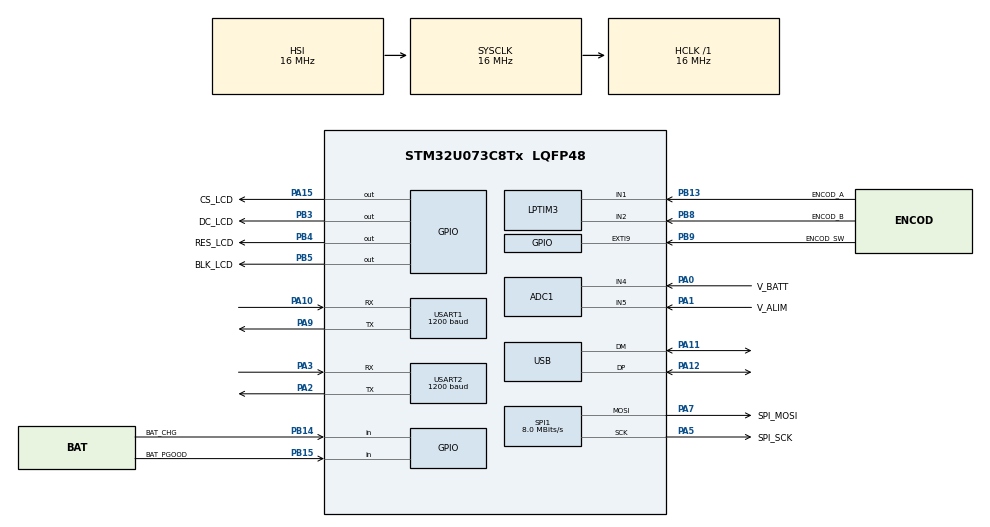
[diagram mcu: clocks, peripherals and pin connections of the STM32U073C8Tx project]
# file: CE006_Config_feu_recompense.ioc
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ADC1.Channel-0\#ChannelRegularConversion=ADC_CHANNEL_4
ADC1.NbrOfConversionFlag=1
ADC1.Rank-0\#ChannelRegularConversion=1
ADC1.RankArg-0\#ChannelRegularConversion=ADC_REGULAR_RANK_1
ADC1.SamplingTime-0\#ChannelRegularConversion=ADC_SAMPLINGTIME_COMMON_1
ADC1.SelectedChannel=ADC_CHANNEL_4|ADC_CHANNEL_5
ADC1.master=1
Mcu.Family=STM32U0
Mcu.Name=STM32U073C8Tx
Mcu.Package=LQFP48
NVIC.EXTI4_15_IRQn=true\:0\:0\:false\:false\:true\:false\:true\:true\:true
NVIC.PriorityGroup=NVIC_PRIORITYGROUP_2
NVIC.TIM1_BRK_UP_TRG_COM_IRQn=true\:3\:0\:false\:false\:true\:false\:false\:true\:true
NVIC.TimeBase=TIM1_BRK_UP_TRG_COM_IRQn
NVIC.TimeBaseIP=TIM1
PA0.GPIO_Label=V_BATT
PA0.Mode=IN4
PA0.Signal=ADC1_IN4
PA1.GPIO_Label=V_ALIM
PA1.Mode=IN5
PA1.Signal=ADC1_IN5
PA10.Mode=Asynchronous
PA10.Signal=USART1_RX
PA11\ [PA9].Mode=Device
PA11\ [PA9].Signal=USB_DM
PA12\ [PA10].Mode=Device
PA12\ [PA10].Signal=USB_DP
PA13\ (SWDIO).GPIO_Label=SWDIO
PA13\ (SWDIO).Signal=DEBUG_JTMS-SWDIO
PA14\ (SWCLK).GPIO_Label=SWCLK
PA14\ (SWCLK).Signal=DEBUG_JTCK-SWCLK
PA15.GPIO_Label=CS_LCD
PA15.Signal=GPIO_Output
PA2.Mode=Asynchronous
PA2.Signal=USART2_TX
PA3.Mode=Asynchronous
PA3.Signal=USART2_RX
PA5.GPIO_Label=SPI_SCK
PA5.Mode=TX_Only_Simplex_Unidirect_Master
PA5.Signal=SPI1_SCK
PA7.GPIO_Label=SPI_MOSI
PA7.Mode=TX_Only_Simplex_Unidirect_Master
PA7.Signal=SPI1_MOSI
PA9.Mode=Asynchronous
PA9.Signal=USART1_TX
PB13.GPIO_Label=ENCOD_A
PB13.Mode=Encoder_mode_occur1
PB13.Signal=LPTIM3_IN1
PB14.GPIO_Label=BAT_CHG
PB14.Signal=GPIO_Input
PB15.GPIO_Label=BAT_PGOOD
PB15.Signal=GPIO_Input
PB3.GPIO_Label=DC_LCD
PB3.Signal=GPIO_Output
PB4.GPIO_Label=RES_LCD
PB4.Signal=GPIO_Output
PB5.GPIO_Label=BLK_LCD
PB5.Signal=GPIO_Output
PB8.GPIO_Label=ENCOD_B
PB8.Mode=Encoder_mode_occur1
PB8.Signal=LPTIM3_IN2
PB9.GPIO_Label=ENCOD_SW
PB9.Signal=GPXTI9
PF0-OSC_IN.Mode=HSE-External-Oscillator
PF0-OSC_IN.Signal=RCC_OSC_IN
PF1-OSC_OUT.Mode=HSE-External-Oscillator
PF1-OSC_OUT.Signal=RCC_OSC_OUT
ProjectManager.HeapSize=0x200
ProjectManager.StackSize=0x400
ProjectManager.TargetToolchain=STM32CubeIDE
RCC.AHBFreq_Value=16000000
RCC.CortexFreq_Value=16000000
RCC.HCLKFreq_Value=16000000
RCC.HSE_VALUE=4000000
RCC.HSI48_VALUE=48000000
RCC.HSI_VALUE=16000000
RCC.LSE_VALUE=32768
RCC.MSI_VALUE=4000000
RCC.SYSCLKFreq_VALUE=16000000
RCC.USBCLockSelection=RCC_USBCLKSOURCE_HSI48
RCC.USBFreq_Value=48000000
RCC.VCOOutputFreq_Value=64000000
SPI1.CalculateBaudRate=8.0 MBits/s
SPI1.Direction=SPI_DIRECTION_2LINES
SPI1.Mode=SPI_MODE_MASTER
SPI1.VirtualType=VM_MASTER
USART1.BaudRate=1200
USART1.Parity=PARITY_ODD
USART1.VirtualMode-Asynchronous=VM_ASYNC
USART1.WordLength=WORDLENGTH_7B
USART2.BaudRate=1200
USART2.Parity=PARITY_ODD
USART2.VirtualMode-Asynchronous=VM_ASYNC
USART2.WordLength=WORDLENGTH_7B
USB.VirtualMode=Device_Only
USBX.BSP.number=1
USBX.Core_System=1
USBX.USBD_CDCACM_EPIN_ADDR=2
USBX.USBD_CDCACM_EPOUT_ADDR=3
USBX.UX_DEVICE_CDC_ACM=1
USBX.UX_Device_Controller=1
USBX.UX_Device_CoreStack=1
USBX0.BSP.STBoard=false
USBX0.BSP.api=Unknown
USBX0.BSP.instance=USB
USBX0.BSP.ip=USB
USBX0.BSP.mode=Device_Only
USBX0.BSP.name=USB_Device
USBX0.BSP.solution=USB
VP_PWR_VS_SECSignals.Mode=Security/Privilege
VP_SYS_VS_tim1.Mode=TIM1
VP_THREADX_VS_RTOSJjThreadXJjCoreJjDefault.Mode=Core_Default
VP_USBX_Core_System.Mode=Core_System
VP_USBX_UX\ Device\ CDC\ ACM\ Class_FS.Mode=UX_Device_class_CDC_ACM_FS
VP_USBX_UX\ Device\ Controller_FS.Mode=UX_Device_Controller_FS
VP_USBX_UX\ Device\ CoreStack_FS.Mode=UX_Device_CoreStack_FS
board=custom

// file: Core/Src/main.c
/* USER CODE BEGIN Header */
/**
  ******************************************************************************
  * @file           : main.c
  * @brief          : Main program body
  ******************************************************************************
  * @attention
  *
  * Copyright (c) 2026 STMicroelectronics.
  * All rights reserved.
  *
  * This software is licensed under terms that can be found in the LICENSE file
  * in the root directory of this software component.
  * If no LICENSE file comes with this software, it is provided AS-IS.
  *
  ******************************************************************************
  */
/* USER CODE END Header */
#include "app_threadx.h"
#include "main.h"

/* USER CODE BEGIN Includes */
#include <stdint.h>

#include "drivers/encoder_driver.h"

/* USER CODE END Includes */

ADC_HandleTypeDef hadc1;

LPTIM_HandleTypeDef hlptim3;

SPI_HandleTypeDef hspi1;

UART_HandleTypeDef huart1;
UART_HandleTypeDef huart2;

PCD_HandleTypeDef hpcd_USB_DRD_FS;

void SystemClock_Config(void);
static void MX_GPIO_Init(void);
static void MX_USART1_UART_Init(void);
static void MX_USART2_UART_Init(void);
static void MX_USB_PCD_Init(void);
static void MX_ADC1_Init(void);
static void MX_LPTIM3_Init(void);
static void MX_SPI1_Init(void);

int main(void)
{

  /* MCU Configuration--------------------------------------------------------*/

  /* Reset of all peripherals, Initializes the Flash interface and the Systick. */
  HAL_Init();

  /* Configure the system clock */
  SystemClock_Config();

  /* Initialize all configured peripherals */
  MX_GPIO_Init();
  MX_USART1_UART_Init();
  MX_USART2_UART_Init();
  MX_USB_PCD_Init();
  MX_ADC1_Init();
  MX_LPTIM3_Init();
  MX_SPI1_Init();
  /* USER CODE BEGIN 2 */

  Encoder_Init();
  int32_t testPositionVal = 0;

  /* USER CODE END 2 */

  MX_ThreadX_Init();

  /* We should never get here as control is now taken by the scheduler */

  /* Infinite loop */
  while (1)
  {

  }
}

void SystemClock_Config(void)
{
  RCC_OscInitTypeDef RCC_OscInitStruct = {0};
  RCC_ClkInitTypeDef RCC_ClkInitStruct = {0};

  /** Configure the main internal regulator output voltage
  */
  HAL_PWREx_ControlVoltageScaling(PWR_REGULATOR_VOLTAGE_SCALE2);

  /** Initializes the RCC Oscillators according to the specified parameters
  * in the RCC_OscInitTypeDef structure.
  */
  RCC_OscInitStruct.OscillatorType = RCC_OSCILLATORTYPE_HSI|RCC_OSCILLATORTYPE_HSI48;
  RCC_OscInitStruct.HSIState = RCC_HSI_ON;
  RCC_OscInitStruct.HSICalibrationValue = RCC_HSICALIBRATION_DEFAULT;
  RCC_OscInitStruct.HSI48State = RCC_HSI48_ON;
  RCC_OscInitStruct.PLL.PLLState = RCC_PLL_NONE;
  if (HAL_RCC_OscConfig(&RCC_OscInitStruct) != HAL_OK)
  {
    Error_Handler();
  }

  /** Initializes the CPU, AHB and APB buses clocks
  */
  RCC_ClkInitStruct.ClockType = RCC_CLOCKTYPE_HCLK|RCC_CLOCKTYPE_SYSCLK
                              |RCC_CLOCKTYPE_PCLK1;
  RCC_ClkInitStruct.SYSCLKSource = RCC_SYSCLKSOURCE_HSI;
  RCC_ClkInitStruct.AHBCLKDivider = RCC_SYSCLK_DIV1;
  RCC_ClkInitStruct.APB1CLKDivider = RCC_HCLK_DIV1;

  if (HAL_RCC_ClockConfig(&RCC_ClkInitStruct, FLASH_LATENCY_1) != HAL_OK)
  {
    Error_Handler();
  }
}

static void MX_ADC1_Init(void)
{

  ADC_ChannelConfTypeDef sConfig = {0};

  /** Configure the global features of the ADC (Clock, Resolution, Data Alignment and number of conversion)
  */
  hadc1.Instance = ADC1;
  hadc1.Init.ClockPrescaler = ADC_CLOCK_SYNC_PCLK_DIV1;
  hadc1.Init.Resolution = ADC_RESOLUTION_12B;
  hadc1.Init.DataAlign = ADC_DATAALIGN_RIGHT;
  hadc1.Init.ScanConvMode = ADC_SCAN_DISABLE;
  hadc1.Init.EOCSelection = ADC_EOC_SINGLE_CONV;
  hadc1.Init.LowPowerAutoWait = DISABLE;
  hadc1.Init.LowPowerAutoPowerOff = DISABLE;
  hadc1.Init.ContinuousConvMode = DISABLE;
  hadc1.Init.NbrOfConversion = 1;
  hadc1.Init.DiscontinuousConvMode = DISABLE;
  hadc1.Init.ExternalTrigConv = ADC_SOFTWARE_START;
  hadc1.Init.ExternalTrigConvEdge = ADC_EXTERNALTRIGCONVEDGE_NONE;
  hadc1.Init.DMAContinuousRequests = DISABLE;
  hadc1.Init.Overrun = ADC_OVR_DATA_PRESERVED;
  hadc1.Init.SamplingTimeCommon1 = ADC_SAMPLETIME_1CYCLE_5;
  hadc1.Init.SamplingTimeCommon2 = ADC_SAMPLETIME_1CYCLE_5;
  hadc1.Init.OversamplingMode = DISABLE;
  hadc1.Init.TriggerFrequencyMode = ADC_TRIGGER_FREQ_HIGH;
  if (HAL_ADC_Init(&hadc1) != HAL_OK)
  {
    Error_Handler();
  }

  /** Configure Regular Channel
  */
  sConfig.Channel = ADC_CHANNEL_4;
  sConfig.Rank = ADC_REGULAR_RANK_1;
  sConfig.SamplingTime = ADC_SAMPLINGTIME_COMMON_1;
  if (HAL_ADC_ConfigChannel(&hadc1, &sConfig) != HAL_OK)
  {
    Error_Handler();
  }

}

static void MX_LPTIM3_Init(void)
{

  hlptim3.Instance = LPTIM3;
  hlptim3.Init.Clock.Source = LPTIM_CLOCKSOURCE_APBCLOCK_LPOSC;
  hlptim3.Init.Clock.Prescaler = LPTIM_PRESCALER_DIV1;
  hlptim3.Init.UltraLowPowerClock.Polarity = LPTIM_CLOCKPOLARITY_RISING;
  hlptim3.Init.UltraLowPowerClock.SampleTime = LPTIM_CLOCKSAMPLETIME_DIRECTTRANSITION;
  hlptim3.Init.Trigger.Source = LPTIM_TRIGSOURCE_SOFTWARE;
  hlptim3.Init.Period = 65535;
  hlptim3.Init.UpdateMode = LPTIM_UPDATE_IMMEDIATE;
  hlptim3.Init.CounterSource = LPTIM_COUNTERSOURCE_EXTERNAL;
  hlptim3.Init.Input1Source = LPTIM_INPUT1SOURCE_GPIO;
  hlptim3.Init.Input2Source = LPTIM_INPUT2SOURCE_GPIO;
  hlptim3.Init.RepetitionCounter = 0;
  if (HAL_LPTIM_Init(&hlptim3) != HAL_OK)
  {
    Error_Handler();
  }

}

static void MX_SPI1_Init(void)
{

  /* SPI1 parameter configuration*/
  hspi1.Instance = SPI1;
  hspi1.Init.Mode = SPI_MODE_MASTER;
  hspi1.Init.Direction = SPI_DIRECTION_2LINES;
  hspi1.Init.DataSize = SPI_DATASIZE_4BIT;
  hspi1.Init.CLKPolarity = SPI_POLARITY_LOW;
  hspi1.Init.CLKPhase = SPI_PHASE_1EDGE;
  hspi1.Init.NSS = SPI_NSS_SOFT;
  hspi1.Init.BaudRatePrescaler = SPI_BAUDRATEPRESCALER_2;
  hspi1.Init.FirstBit = SPI_FIRSTBIT_MSB;
  hspi1.Init.TIMode = SPI_TIMODE_DISABLE;
  hspi1.Init.CRCCalculation = SPI_CRCCALCULATION_DISABLE;
  hspi1.Init.CRCPolynomial = 7;
  hspi1.Init.CRCLength = SPI_CRC_LENGTH_DATASIZE;
  hspi1.Init.NSSPMode = SPI_NSS_PULSE_ENABLE;
  if (HAL_SPI_Init(&hspi1) != HAL_OK)
  {
    Error_Handler();
  }

}

static void MX_USART1_UART_Init(void)
{

  huart1.Instance = USART1;
  huart1.Init.BaudRate = 1200;
  huart1.Init.WordLength = UART_WORDLENGTH_7B;
  huart1.Init.StopBits = UART_STOPBITS_1;
  huart1.Init.Parity = UART_PARITY_ODD;
  huart1.Init.Mode = UART_MODE_TX_RX;
  huart1.Init.HwFlowCtl = UART_HWCONTROL_NONE;
  huart1.Init.OverSampling = UART_OVERSAMPLING_16;
  huart1.Init.OneBitSampling = UART_ONE_BIT_SAMPLE_DISABLE;
  huart1.Init.ClockPrescaler = UART_PRESCALER_DIV1;
  huart1.AdvancedInit.AdvFeatureInit = UART_ADVFEATURE_NO_INIT;
  if (HAL_UART_Init(&huart1) != HAL_OK)
  {
    Error_Handler();
  }
  if (HAL_UARTEx_SetTxFifoThreshold(&huart1, UART_TXFIFO_THRESHOLD_1_8) != HAL_OK)
  {
    Error_Handler();
  }
  if (HAL_UARTEx_SetRxFifoThreshold(&huart1, UART_RXFIFO_THRESHOLD_1_8) != HAL_OK)
  {
    Error_Handler();
  }
  if (HAL_UARTEx_DisableFifoMode(&huart1) != HAL_OK)
  {
    Error_Handler();
  }

}

static void MX_USART2_UART_Init(void)
{

  huart2.Instance = USART2;
  huart2.Init.BaudRate = 1200;
  huart2.Init.WordLength = UART_WORDLENGTH_7B;
  huart2.Init.StopBits = UART_STOPBITS_1;
  huart2.Init.Parity = UART_PARITY_ODD;
  huart2.Init.Mode = UART_MODE_TX_RX;
  huart2.Init.HwFlowCtl = UART_HWCONTROL_NONE;
  huart2.Init.OverSampling = UART_OVERSAMPLING_16;
  huart2.Init.OneBitSampling = UART_ONE_BIT_SAMPLE_DISABLE;
  huart2.Init.ClockPrescaler = UART_PRESCALER_DIV1;
  huart2.AdvancedInit.AdvFeatureInit = UART_ADVFEATURE_NO_INIT;
  if (HAL_UART_Init(&huart2) != HAL_OK)
  {
    Error_Handler();
  }
  if (HAL_UARTEx_SetTxFifoThreshold(&huart2, UART_TXFIFO_THRESHOLD_1_8) != HAL_OK)
  {
    Error_Handler();
  }
  if (HAL_UARTEx_SetRxFifoThreshold(&huart2, UART_RXFIFO_THRESHOLD_1_8) != HAL_OK)
  {
    Error_Handler();
  }
  if (HAL_UARTEx_DisableFifoMode(&huart2) != HAL_OK)
  {
    Error_Handler();
  }

}

static void MX_USB_PCD_Init(void)
{

  hpcd_USB_DRD_FS.Instance = USB_DRD_FS;
  hpcd_USB_DRD_FS.Init.dev_endpoints = 8;
  hpcd_USB_DRD_FS.Init.speed = USBD_FS_SPEED;
  hpcd_USB_DRD_FS.Init.phy_itface = PCD_PHY_EMBEDDED;
  hpcd_USB_DRD_FS.Init.Sof_enable = DISABLE;
  hpcd_USB_DRD_FS.Init.low_power_enable = DISABLE;
  hpcd_USB_DRD_FS.Init.lpm_enable = DISABLE;
  hpcd_USB_DRD_FS.Init.battery_charging_enable = DISABLE;
  if (HAL_PCD_Init(&hpcd_USB_DRD_FS) != HAL_OK)
  {
    Error_Handler();
  }

}

static void MX_GPIO_Init(void)
{
  GPIO_InitTypeDef GPIO_InitStruct = {0};

  /* GPIO Ports Clock Enable */
  __HAL_RCC_GPIOF_CLK_ENABLE();
  __HAL_RCC_GPIOA_CLK_ENABLE();
  __HAL_RCC_GPIOB_CLK_ENABLE();

  /*Configure GPIO pin Output Level */
  HAL_GPIO_WritePin(CS_LCD_GPIO_Port, CS_LCD_Pin, GPIO_PIN_RESET);

  /*Configure GPIO pin Output Level */
  HAL_GPIO_WritePin(GPIOB, DC_LCD_Pin|RES_LCD_Pin|BLK_LCD_Pin, GPIO_PIN_RESET);

  /*Configure GPIO pins : BAT_CHG_Pin BAT_PGOOD_Pin */
  GPIO_InitStruct.Pin = BAT_CHG_Pin|BAT_PGOOD_Pin;
  GPIO_InitStruct.Mode = GPIO_MODE_INPUT;
  GPIO_InitStruct.Pull = GPIO_NOPULL;
  HAL_GPIO_Init(GPIOB, &GPIO_InitStruct);

  /*Configure GPIO pin : CS_LCD_Pin */
  GPIO_InitStruct.Pin = CS_LCD_Pin;
  GPIO_InitStruct.Mode = GPIO_MODE_OUTPUT_PP;
  GPIO_InitStruct.Pull = GPIO_NOPULL;
  GPIO_InitStruct.Speed = GPIO_SPEED_FREQ_LOW;
  HAL_GPIO_Init(CS_LCD_GPIO_Port, &GPIO_InitStruct);

  /*Configure GPIO pins : DC_LCD_Pin RES_LCD_Pin BLK_LCD_Pin */
  GPIO_InitStruct.Pin = DC_LCD_Pin|RES_LCD_Pin|BLK_LCD_Pin;
  GPIO_InitStruct.Mode = GPIO_MODE_OUTPUT_PP;
  GPIO_InitStruct.Pull = GPIO_NOPULL;
  GPIO_InitStruct.Speed = GPIO_SPEED_FREQ_LOW;
  HAL_GPIO_Init(GPIOB, &GPIO_InitStruct);

  /*Configure GPIO pin : ENCOD_SW_Pin */
  GPIO_InitStruct.Pin = ENCOD_SW_Pin;
  GPIO_InitStruct.Mode = GPIO_MODE_IT_RISING;
  GPIO_InitStruct.Pull = GPIO_NOPULL;
  HAL_GPIO_Init(ENCOD_SW_GPIO_Port, &GPIO_InitStruct);

  /* EXTI interrupt init*/
  HAL_NVIC_SetPriority(EXTI4_15_IRQn, 0, 0);
  HAL_NVIC_EnableIRQ(EXTI4_15_IRQn);

}

void HAL_TIM_PeriodElapsedCallback(TIM_HandleTypeDef *htim)
{
  if (htim->Instance == TIM1)
  {
    HAL_IncTick();
  }
}

void Error_Handler(void)
{
  __disable_irq();
  while (1)
  {
  }
}
